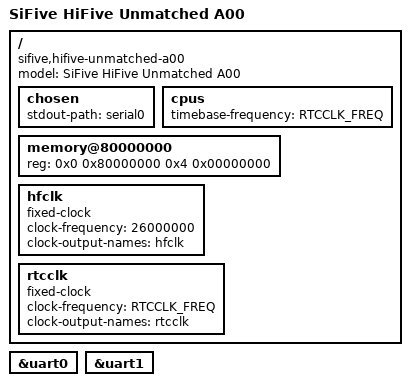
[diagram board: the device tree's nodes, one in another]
// SPDX-License-Identifier: (GPL-2.0 OR MIT)
/* Copyright (c) 2020 SiFive, Inc */

#include "custom.dtsi"
#include <dt-bindings/interrupt-controller/irq.h>

/* Clock frequency (in Hz) of the PCB crystal for rtcclk */
#define RTCCLK_FREQ		1000000

/ {
	model = "SiFive HiFive Unmatched A00";
	compatible = "sifive,hifive-unmatched-a00", "sifive,fu740-c000",
		     "sifive,fu740";

	chosen {
		stdout-path = "serial0";
	};

	cpus {
		timebase-frequency = <RTCCLK_FREQ>;
	};

	memory@80000000 {
		device_type = "memory";
		reg = <0x0 0x80000000 0x4 0x00000000>;
	};

	hfclk: hfclk {
		#clock-cells = <0>;
		compatible = "fixed-clock";
		clock-frequency = <26000000>;
		clock-output-names = "hfclk";
	};

	rtcclk: rtcclk {
		#clock-cells = <0>;
		compatible = "fixed-clock";
		clock-frequency = <RTCCLK_FREQ>;
		clock-output-names = "rtcclk";
	};
};

&uart0 {
	status = "okay";
};

&uart1 {
	status = "okay";
};

